# PIC18F25Q10 register map
Vendor: Microchip
Registers are 8-bit, read-write, reset 0x0 unless marked. A register's access mark holds for its fields unless they carry their own. Addresses are absolute, and some are shared; only a register's first bit layout is shown; [hi:lo] are bit positions; {n}, {i} and the like mark numbered series; 'fields as' and 'values as' point back to an identical list.

## lvd_ctrl
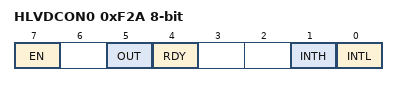
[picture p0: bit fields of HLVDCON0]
0xF2A HLVDCON0 reset not defined — (power-on value 0-xx--00)
  [7] EN, [5] OUT ro, [4] RDY ro, [1] INTH, [0] INTL
0xF2B HLVDCON1
  [3:0] SEL

## amp_fvr_ts_ctrl
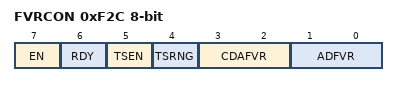
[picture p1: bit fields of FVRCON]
0xF2C FVRCON reset not defined — (power-on value xx000000)
  [7] EN — Zero-Cross Detect Software Enable bit
  [6] RDY ro
  [5] TSEN — Zero-Cross Detect Data Output
  [4] TSRNG — Zero-Cross Detect Polarity bit
  [3:2] CDAFVR
  [1:0] ADFVR — Zero-Cross Detect Positive-going Edge Interrupt Enable

## cmp_zxover_ctrl
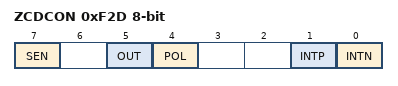
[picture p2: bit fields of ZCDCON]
0xF2D ZCDCON reset not defined — ZERO CROSS DETECT CONTROL REGISTER (power-on value 0-x0--00)
  [7] SEN — Zero-Cross Detect Software Enable bit
  [5] OUT ro — Zero-Cross Detect Data Output
  [4] POL — Zero-Cross Detect Polarity bit
  [1] INTP — Zero-Cross Detect Positive-going Edge Interrupt Enable
  [0] INTN — Zero-Cross Detect Negative-going Edge Interrupt Enable

## dac_nbit_ctrl
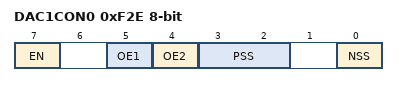
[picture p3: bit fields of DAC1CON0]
0xF2E DAC1CON0
  [7] EN, [5] OE1, [4] OE2, [3:2] PSS, [0] NSS
0xF2F DAC1CON1 reset not defined — (power-on value ---xxxxx)
  [4:0] DAC1R

## cmp_rr_ctrl
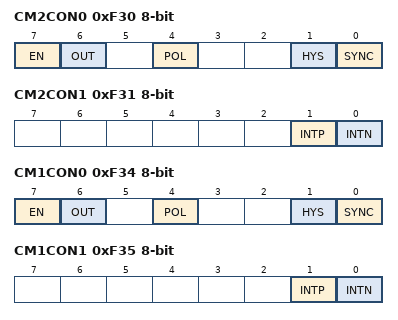
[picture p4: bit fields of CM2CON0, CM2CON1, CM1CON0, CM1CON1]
0xF30 CM2CON0 — COMPARATOR CONTROL REGISTER 0
  [7] EN — Comparator Enable bit
  [6] OUT ro — Comparator Output bit
  [4] POL — Comparator Output Polarity Select bit
  [1] HYS — Comparator Hysteresis Enable bit
  [0] SYNC — Comparator Output Synchronous Mode bit
0xF31 CM2CON1 — COMPARATOR CONTROL REGISTER 1
  [1] INTP — Comparator Interrupt on Positive going edge Enable bits
  [0] INTN — Comparator Interrupt on Negative going edge Enable bits
0xF32 CM2NCH — COMPARATOR INVERTING CHANNEL SELECT REGISTER
  [2:0] NCH — Comparator Inverting Input Channel Select bits
0xF33 CM2PCH — COMPARATOR NON-INVERTING CHANNEL SELECT REGISTER
  [2:0] PCH — Comparator Non-Inverting Input Channel Select bits
0xF34 CM1CON0 — COMPARATOR CONTROL REGISTER 0
  fields as CM2CON0
0xF35 CM1CON1 — COMPARATOR CONTROL REGISTER 1
  fields as CM2CON1
0xF36 CM1NCH — COMPARATOR INVERTING CHANNEL SELECT REGISTER
  [2:0] NCH — Comparator Inverting Input Channel Select bits
0xF37 CM1PCH — COMPARATOR NON-INVERTING CHANNEL SELECT REGISTER
  [2:0] PCH — Comparator Non-Inverting Input Channel Select bits

## wg_cwg
0xF3B CWG1CLK
  [0] CS
0xF3C CWG1ISM
  [4:0] IS
0xF3D CWG1DBR
  [5:0] DBR
0xF3E CWG1DBF
  [5:0] DBF
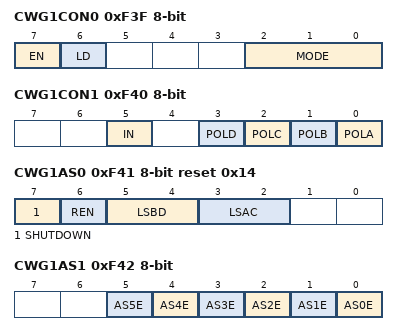
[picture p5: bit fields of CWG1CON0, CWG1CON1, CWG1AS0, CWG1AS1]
0xF3F CWG1CON0
  [7] EN, [6] LD, [2:0] MODE
0xF40 CWG1CON1 reset not defined — (power-on value --x-0000)
  [5] IN ro, [3] POLD, [2] POLC, [1] POLB, [0] POLA
0xF41 CWG1AS0 reset 0x14
  [7] SHUTDOWN, [6] REN, [5:4] LSBD, [3:2] LSAC
0xF42 CWG1AS1
  [n] AS{n}E (n=0..5)
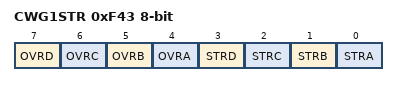
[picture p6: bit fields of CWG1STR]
0xF43 CWG1STR
  [7] OVRD, [6] OVRC, [5] OVRB, [4] OVRA, [3] STRD, [2] STRC, [1] STRB, [0] STRA

## dma_nvm
0xF44 SCANLADRL
  [7:0] LADR
0xF45 SCANLADRH
  [7:0] LADR
0xF46 SCANLADRU
  [5:0] LADR
0xF47 SCANHADRL reset 0xFF
  [7:0] HADR
0xF48 SCANHADRH reset 0xFF
  [7:0] HADR
0xF49 SCANHADRU reset 0x3F
  [5:0] HADR
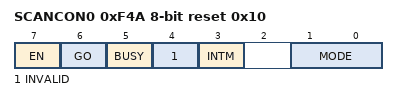
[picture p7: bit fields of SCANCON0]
0xF4A SCANCON0 reset 0x10
  [7] EN, [6] GO, [5] BUSY ro, [4] INVALID ro, [3] INTM, [1:0] MODE
0xF4B SCANTRIG
  [3:0] TSEL

## txm_mod
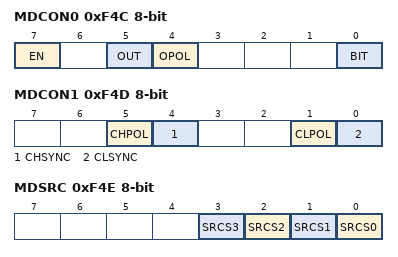
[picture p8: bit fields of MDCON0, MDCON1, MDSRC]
0xF4C MDCON0
  [7] EN, [5] OUT, [4] OPOL, [0] BIT
0xF4D MDCON1
  [5] CHPOL, [4] CHSYNC, [1] CLPOL, [0] CLSYNC
0xF4E MDSRC
  [n] SRCS{n} (n=0..3)
0xF4F MDCARL
  [2:0] CLS
0xF50 MDCARH
  [2:0] CHS

## adc_sarcore_mp_ctrl
0xF51 ADACT
  [4:0] ADACT
0xF52 ADCLK
  [5:0] ADCS
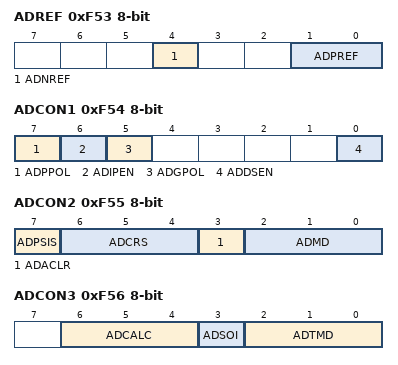
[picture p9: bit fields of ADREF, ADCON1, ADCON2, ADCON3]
0xF53 ADREF
  [4] ADNREF, [1:0] ADPREF
0xF54 ADCON1
  [7] ADPPOL, [6] ADIPEN, [5] ADGPOL, [0] ADDSEN
0xF55 ADCON2
  [7] ADPSIS, [6:4] ADCRS, [3] ADACLR, [2:0] ADMD
0xF56 ADCON3
  [6:4] ADCALC, [3] ADSOI, [2:0] ADTMD
0xF57 ADACQ
0xF58 ADCAP
  [4:0] ADCAP
0xF59 ADPRE
0xF5A ADPCH
  [5:0] ADPCH
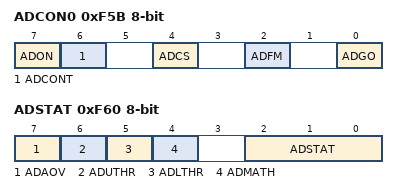
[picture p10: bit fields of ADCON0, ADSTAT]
0xF5B ADCON0
  [7] ADON, [6] ADCONT, [4] ADCS, [2] ADFM, [0] ADGO
0xF5C ADPREVL ro
0xF5D ADPREVH ro
0xF5E ADRESL
0xF5F ADRESH
0xF60 ADSTAT
  [7] ADAOV, [6] ADUTHR ro, [5] ADLTHR ro, [4] ADMATH ro, [2:0] ADSTAT ro
0xF61 ADRPT
0xF62 ADCNT
0xF63 ADSTPTL
0xF64 ADSTPTH
0xF65 ADLTHL
0xF66 ADLTHH
0xF67 ADUTHL
0xF68 ADUTHH
0xF69 ADERRL ro
0xF6A ADERRH ro
0xF6B ADACCL reset not defined — (power-on value xxxxxxxx)
0xF6C ADACCH reset not defined — (power-on value xxxxxxxx)
0xF6D ADFLTRL ro reset not defined — (power-on value xxxxxxxx)
0xF6E ADFLTRH ro reset not defined — (power-on value xxxxxxxx)
